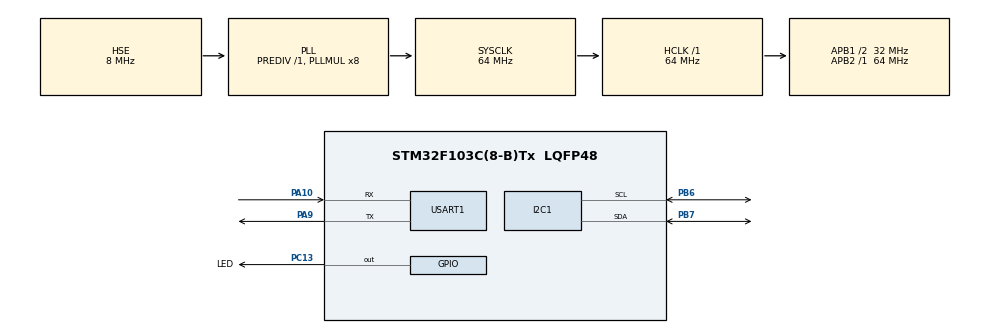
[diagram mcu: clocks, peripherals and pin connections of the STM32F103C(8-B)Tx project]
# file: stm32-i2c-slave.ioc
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Dma.I2C1_RX.0.Direction=DMA_PERIPH_TO_MEMORY
Dma.I2C1_RX.0.Instance=DMA1_Channel7
Dma.I2C1_RX.0.MemDataAlignment=DMA_MDATAALIGN_BYTE
Dma.I2C1_RX.0.MemInc=DMA_MINC_ENABLE
Dma.I2C1_RX.0.Mode=DMA_NORMAL
Dma.I2C1_RX.0.PeriphDataAlignment=DMA_PDATAALIGN_BYTE
Dma.I2C1_RX.0.PeriphInc=DMA_PINC_DISABLE
Dma.I2C1_RX.0.Priority=DMA_PRIORITY_HIGH
Dma.I2C1_TX.1.Direction=DMA_MEMORY_TO_PERIPH
Dma.I2C1_TX.1.Instance=DMA1_Channel6
Dma.I2C1_TX.1.MemDataAlignment=DMA_MDATAALIGN_BYTE
Dma.I2C1_TX.1.MemInc=DMA_MINC_ENABLE
Dma.I2C1_TX.1.Mode=DMA_NORMAL
Dma.I2C1_TX.1.PeriphDataAlignment=DMA_PDATAALIGN_BYTE
Dma.I2C1_TX.1.PeriphInc=DMA_PINC_DISABLE
Dma.I2C1_TX.1.Priority=DMA_PRIORITY_HIGH
Dma.Request0=I2C1_RX
Dma.Request1=I2C1_TX
Dma.Request2=USART1_TX
Dma.Request3=USART1_RX
Dma.USART1_RX.3.Direction=DMA_PERIPH_TO_MEMORY
Dma.USART1_RX.3.Instance=DMA1_Channel5
Dma.USART1_RX.3.MemDataAlignment=DMA_MDATAALIGN_BYTE
Dma.USART1_RX.3.MemInc=DMA_MINC_ENABLE
Dma.USART1_RX.3.Mode=DMA_NORMAL
Dma.USART1_RX.3.PeriphDataAlignment=DMA_PDATAALIGN_BYTE
Dma.USART1_RX.3.PeriphInc=DMA_PINC_DISABLE
Dma.USART1_RX.3.Priority=DMA_PRIORITY_LOW
Dma.USART1_TX.2.Direction=DMA_MEMORY_TO_PERIPH
Dma.USART1_TX.2.Instance=DMA1_Channel4
Dma.USART1_TX.2.MemDataAlignment=DMA_MDATAALIGN_BYTE
Dma.USART1_TX.2.MemInc=DMA_MINC_ENABLE
Dma.USART1_TX.2.Mode=DMA_NORMAL
Dma.USART1_TX.2.PeriphDataAlignment=DMA_PDATAALIGN_BYTE
Dma.USART1_TX.2.PeriphInc=DMA_PINC_DISABLE
Dma.USART1_TX.2.Priority=DMA_PRIORITY_LOW
I2C1.DualAddressMode=I2C_DUALADDRESS_DISABLE
I2C1.NoStretchMode=I2C_NOSTRETCH_DISABLE
I2C1.OwnAddress=0x68
Mcu.Family=STM32F1
Mcu.Name=STM32F103C(8-B)Tx
Mcu.Package=LQFP48
NVIC.DMA1_Channel4_IRQn=true\:0\:0\:false\:false\:true\:false\:true
NVIC.DMA1_Channel5_IRQn=true\:0\:0\:false\:false\:true\:false\:true
NVIC.DMA1_Channel6_IRQn=true\:0\:0\:false\:false\:true\:false\:true
NVIC.DMA1_Channel7_IRQn=true\:0\:0\:false\:false\:true\:false\:true
NVIC.I2C1_ER_IRQn=true\:0\:0\:false\:false\:true\:true\:true
NVIC.I2C1_EV_IRQn=true\:0\:0\:false\:false\:true\:true\:true
NVIC.PriorityGroup=NVIC_PRIORITYGROUP_4
NVIC.USART1_IRQn=true\:0\:0\:false\:false\:true\:true\:true
PA10.Mode=Asynchronous
PA10.Signal=USART1_RX
PA13.Mode=Serial_Wire
PA13.Signal=SYS_JTMS-SWDIO
PA14.Mode=Serial_Wire
PA14.Signal=SYS_JTCK-SWCLK
PA9.Mode=Asynchronous
PA9.Signal=USART1_TX
PB6.Mode=I2C
PB6.Signal=I2C1_SCL
PB7.Mode=I2C
PB7.Signal=I2C1_SDA
PC13-TAMPER-RTC.GPIO_Label=LED
PC13-TAMPER-RTC.GPIO_ModeDefaultOutputPP=GPIO_MODE_OUTPUT_OD
PC13-TAMPER-RTC.GPIO_Speed=GPIO_SPEED_FREQ_HIGH
PC13-TAMPER-RTC.PinState=GPIO_PIN_SET
PC13-TAMPER-RTC.Signal=GPIO_Output
PD0-OSC_IN.Mode=HSE-External-Oscillator
PD0-OSC_IN.Signal=RCC_OSC_IN
PD1-OSC_OUT.Mode=HSE-External-Oscillator
PD1-OSC_OUT.Signal=RCC_OSC_OUT
ProjectManager.HeapSize=0x200
ProjectManager.StackSize=0x400
ProjectManager.TargetToolchain=STM32CubeIDE
RCC.AHBFreq_Value=64000000
RCC.APB1CLKDivider=RCC_HCLK_DIV2
RCC.APB1Freq_Value=32000000
RCC.APB1TimFreq_Value=64000000
RCC.APB2Freq_Value=64000000
RCC.APB2TimFreq_Value=64000000
RCC.HCLKFreq_Value=64000000
RCC.PLLMUL=RCC_PLL_MUL8
RCC.PLLSourceVirtual=RCC_PLLSOURCE_HSE
RCC.SYSCLKFreq_VALUE=64000000
RCC.SYSCLKSource=RCC_SYSCLKSOURCE_PLLCLK
RCC.USBFreq_Value=64000000
USART1.VirtualMode=VM_ASYNC
board=custom

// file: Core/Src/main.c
/* USER CODE BEGIN Header */
/**
  ******************************************************************************
  * @file           : main.c
  * @brief          : Main program body
  ******************************************************************************
  * @attention
  *
  * <h2><center>&copy; Copyright (c) 2020 STMicroelectronics.
  * All rights reserved.</center></h2>
  *
  * This software component is licensed by ST under BSD 3-Clause license,
  * the "License"; You may not use this file except in compliance with the
  * License. You may obtain a copy of the License at:
  *                        opensource.org/licenses/BSD-3-Clause
  *
  ******************************************************************************
  */
/* USER CODE END Header */

#include "main.h"

I2C_HandleTypeDef hi2c1;
DMA_HandleTypeDef hdma_i2c1_rx;
DMA_HandleTypeDef hdma_i2c1_tx;

UART_HandleTypeDef huart1;
DMA_HandleTypeDef hdma_usart1_tx;
DMA_HandleTypeDef hdma_usart1_rx;

void SystemClock_Config(void);
static void MX_GPIO_Init(void);
static void MX_DMA_Init(void);
static void MX_I2C1_Init(void);
static void MX_USART1_UART_Init(void);

/* USER CODE BEGIN 0 */
int user_main();
/* USER CODE END 0 */

int main(void)
{

  /* MCU Configuration--------------------------------------------------------*/

  /* Reset of all peripherals, Initializes the Flash interface and the Systick. */
  HAL_Init();

  /* Configure the system clock */
  SystemClock_Config();

  /* Initialize all configured peripherals */
  MX_GPIO_Init();
  MX_DMA_Init();
  MX_I2C1_Init();
  MX_USART1_UART_Init();
  /* USER CODE BEGIN 2 */
  user_main();
  /* USER CODE END 2 */

  /* Infinite loop */

}

void SystemClock_Config(void)
{
  RCC_OscInitTypeDef RCC_OscInitStruct = {0};
  RCC_ClkInitTypeDef RCC_ClkInitStruct = {0};

  /** Initializes the CPU, AHB and APB busses clocks
  */
  RCC_OscInitStruct.OscillatorType = RCC_OSCILLATORTYPE_HSE;
  RCC_OscInitStruct.HSEState = RCC_HSE_ON;
  RCC_OscInitStruct.HSEPredivValue = RCC_HSE_PREDIV_DIV1;
  RCC_OscInitStruct.HSIState = RCC_HSI_ON;
  RCC_OscInitStruct.PLL.PLLState = RCC_PLL_ON;
  RCC_OscInitStruct.PLL.PLLSource = RCC_PLLSOURCE_HSE;
  RCC_OscInitStruct.PLL.PLLMUL = RCC_PLL_MUL8;
  if (HAL_RCC_OscConfig(&RCC_OscInitStruct) != HAL_OK)
  {
    Error_Handler();
  }
  /** Initializes the CPU, AHB and APB busses clocks
  */
  RCC_ClkInitStruct.ClockType = RCC_CLOCKTYPE_HCLK|RCC_CLOCKTYPE_SYSCLK
                              |RCC_CLOCKTYPE_PCLK1|RCC_CLOCKTYPE_PCLK2;
  RCC_ClkInitStruct.SYSCLKSource = RCC_SYSCLKSOURCE_PLLCLK;
  RCC_ClkInitStruct.AHBCLKDivider = RCC_SYSCLK_DIV1;
  RCC_ClkInitStruct.APB1CLKDivider = RCC_HCLK_DIV2;
  RCC_ClkInitStruct.APB2CLKDivider = RCC_HCLK_DIV1;

  if (HAL_RCC_ClockConfig(&RCC_ClkInitStruct, FLASH_LATENCY_2) != HAL_OK)
  {
    Error_Handler();
  }
}

static void MX_I2C1_Init(void)
{

  hi2c1.Instance = I2C1;
  hi2c1.Init.ClockSpeed = 100000;
  hi2c1.Init.DutyCycle = I2C_DUTYCYCLE_2;
  hi2c1.Init.OwnAddress1 = 208;
  hi2c1.Init.AddressingMode = I2C_ADDRESSINGMODE_7BIT;
  hi2c1.Init.DualAddressMode = I2C_DUALADDRESS_DISABLE;
  hi2c1.Init.OwnAddress2 = 0;
  hi2c1.Init.GeneralCallMode = I2C_GENERALCALL_DISABLE;
  hi2c1.Init.NoStretchMode = I2C_NOSTRETCH_DISABLE;
  if (HAL_I2C_Init(&hi2c1) != HAL_OK)
  {
    Error_Handler();
  }

}

static void MX_USART1_UART_Init(void)
{

  huart1.Instance = USART1;
  huart1.Init.BaudRate = 115200;
  huart1.Init.WordLength = UART_WORDLENGTH_8B;
  huart1.Init.StopBits = UART_STOPBITS_1;
  huart1.Init.Parity = UART_PARITY_NONE;
  huart1.Init.Mode = UART_MODE_TX_RX;
  huart1.Init.HwFlowCtl = UART_HWCONTROL_NONE;
  huart1.Init.OverSampling = UART_OVERSAMPLING_16;
  if (HAL_UART_Init(&huart1) != HAL_OK)
  {
    Error_Handler();
  }

}

static void MX_DMA_Init(void)
{

  /* DMA controller clock enable */
  __HAL_RCC_DMA1_CLK_ENABLE();

  /* DMA interrupt init */
  /* DMA1_Channel4_IRQn interrupt configuration */
  HAL_NVIC_SetPriority(DMA1_Channel4_IRQn, 0, 0);
  HAL_NVIC_EnableIRQ(DMA1_Channel4_IRQn);
  /* DMA1_Channel5_IRQn interrupt configuration */
  HAL_NVIC_SetPriority(DMA1_Channel5_IRQn, 0, 0);
  HAL_NVIC_EnableIRQ(DMA1_Channel5_IRQn);
  /* DMA1_Channel6_IRQn interrupt configuration */
  HAL_NVIC_SetPriority(DMA1_Channel6_IRQn, 0, 0);
  HAL_NVIC_EnableIRQ(DMA1_Channel6_IRQn);
  /* DMA1_Channel7_IRQn interrupt configuration */
  HAL_NVIC_SetPriority(DMA1_Channel7_IRQn, 0, 0);
  HAL_NVIC_EnableIRQ(DMA1_Channel7_IRQn);

}

static void MX_GPIO_Init(void)
{
  GPIO_InitTypeDef GPIO_InitStruct = {0};

  /* GPIO Ports Clock Enable */
  __HAL_RCC_GPIOC_CLK_ENABLE();
  __HAL_RCC_GPIOD_CLK_ENABLE();
  __HAL_RCC_GPIOA_CLK_ENABLE();
  __HAL_RCC_GPIOB_CLK_ENABLE();

  /*Configure GPIO pin Output Level */
  HAL_GPIO_WritePin(LED_GPIO_Port, LED_Pin, GPIO_PIN_SET);

  /*Configure GPIO pin : LED_Pin */
  GPIO_InitStruct.Pin = LED_Pin;
  GPIO_InitStruct.Mode = GPIO_MODE_OUTPUT_OD;
  GPIO_InitStruct.Pull = GPIO_NOPULL;
  GPIO_InitStruct.Speed = GPIO_SPEED_FREQ_HIGH;
  HAL_GPIO_Init(LED_GPIO_Port, &GPIO_InitStruct);

}

void Error_Handler(void)
{
}

/************************ (C) COPYRIGHT STMicroelectronics *****END OF FILE****/
